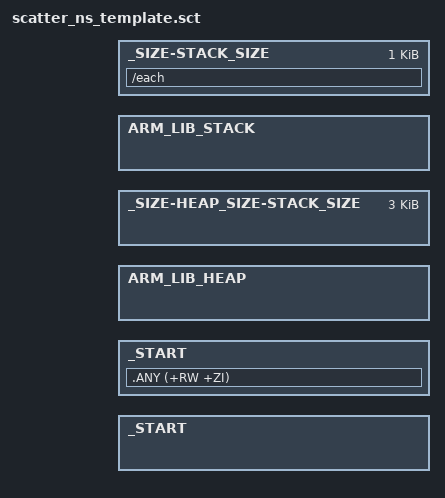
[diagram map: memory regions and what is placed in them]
#! armclang -E --target=arm-arm-none-eabi -mcpu=cortex-m33 -I../ -xc

#include "mem_layout.h"

; *------- <<< Use Configuration Wizard in Context Menu >>> ------------------

;<h> Stack Configuration
;  <o> Stack Size (in Bytes) <0x0-0xFFFFFFFF:8>
;</h>
#define STACK_SIZE 0x400

;<h> Heap Configuration
;  <o> Heap Size (in Bytes) <0x0-0xFFFFFFFF:8>
;</h>
#define HEAP_SIZE 0xC00

; *-------------- <<< end of configuration section >>> -----------------------
{{! For the sake of simplicity, I consider that the regions in the fzone are already sorted by start address }}
{{setVar "first_LR" "true" ~}}
{{! Loop on all regions to get the non secure ones }}
{{#each fzone.system.memory as |memory|}}
{{#if (eq memory.security.n "1")}}
{{! Make sure it is not the global FLASH declaration using the presence of the parent field: this should be improved ? }}
{{#if memory.parent}}
{{#if (eq ../first_LR "true")}}
{{setVar "first_LR" "false" ~}}
LR_{{memory.name}} REGION_{{memory.name}}_START REGION_{{memory.name}}_SIZE {
{{#if (eq memory.access.x "1")}}
{{! First executable region receives the reset handler }}
  ER_{{memory.name}} REGION_{{memory.name}}_START REGION_{{memory.name}}_SIZE {
  	* (RESET,+FIRST)
    * (InRoot$$Sections)
    .ANY (+RO +XO)
  }
{{/if}}
{{! Add all data regions to first load region }}
{{setVar "first_DR" "true" ~}}
{{#each @root.fzone.system.memory as |data_memory|}}
{{#if (and (eq data_memory.security.n "1") (eq data_memory.access.w "1"))}}
{{! Make sure it is not the global SRAM declaration using the presence of the parent field: this should be improved ? }}
{{#if data_memory.parent}}
{{#if (eq ../../first_DR "true")}}
{{setVar "first_DR" "false" ~}}
{{! Only the first data region of the first load region deals with STACK and HEAP }}
  RW_{{data_memory.name}} REGION_{{data_memory.name}}_START REGION_{{data_memory.name}}_SIZE-HEAP_SIZE-STACK_SIZE {
    .ANY (+RW +ZI)
  }
#if HEAP_SIZE>0
  ARM_LIB_HEAP REGION_{{data_memory.name}}_START+REGION_{{data_memory.name}}_SIZE-HEAP_SIZE-STACK_SIZE EMPTY HEAP_SIZE {
  }
#endif
#if STACK_SIZE>0
  ARM_LIB_STACK REGION_{{data_memory.name}}_START+REGION_{{data_memory.name}}_SIZE-STACK_SIZE EMPTY STACK_SIZE {
  }
#endif
{{else}}
; *---- not the first data region {{data_memory.name}}: not handled in this template as in our example we have only one secure DR ----
{{/if}}
{{/if}}
{{/if}}
{{/each}}
{{else}}
{{#if (eq memory.access.w "1")}}
; *---- data region already handled in the first load region : skip {{memory.name}} ----
{{else}}
; *---- not the first load region {{memory.name}}: not handled in this template as in our example we have only one secure LR ----
{{/if}}
}
{{/if}}
{{/if}}
{{/if}}
{{/each}}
